AUTOSAR XML (schema 4-2-2)
package /STELLANTIS/EPT/COMSWCs
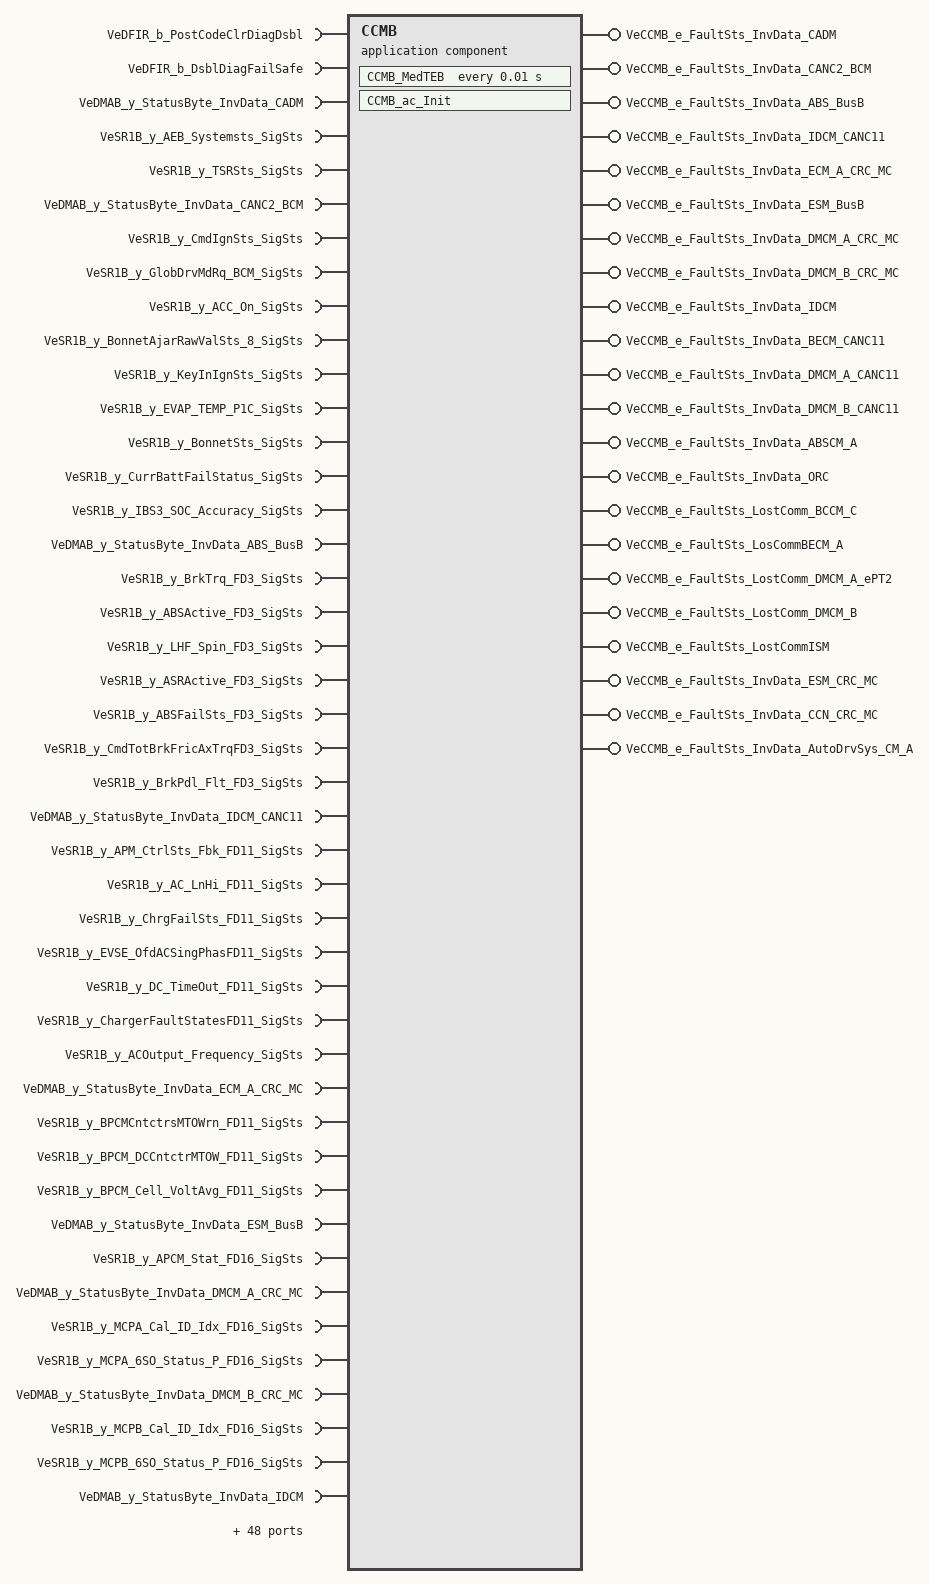
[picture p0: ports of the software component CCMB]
  application sw component type CCMB
    92 x require port, all with nonqueued-receiver-com-spec{data-element=Value, init-value=0}:
      VeDFIR_b_PostCodeClrDiagDsbl: variation-point={short-label=vpVeDFIR_b_PostCodeClrDiagDsbl, sw-syscond=1}, required-interface=VeDFIR_b_PostCodeClrDiagDsbl
      VeDFIR_b_DsblDiagFailSafe: variation-point={short-label=vpVeDFIR_b_DsblDiagFailSafe, sw-syscond=1}, required-interface=VeDFIR_b_DsblDiagFailSafe
      VeDMAB_y_StatusByte_InvData_CADM: variation-point={short-label=vpVeDMAB_y_StatusByte_InvData_CADM, sw-syscond=1}, required-interface=VeDMAB_y_StatusByte_InvData_CADM
      VeSR1B_y_AEB_Systemsts_SigSts: variation-point={short-label=vpVeSR1B_y_AEB_Systemsts_SigSts, sw-syscond=1}, required-interface=VeSR1B_y_AEB_Systemsts_SigSts
      VeSR1B_y_TSRSts_SigSts: variation-point={short-label=vpVeSR1B_y_TSRSts_SigSts, sw-syscond=1}, required-interface=VeSR1B_y_TSRSts_SigSts
      VeDMAB_y_StatusByte_InvData_CANC2_BCM: variation-point={short-label=vpVeDMAB_y_StatusByte_InvData_CANC2_BCM, sw-syscond=1}, required-interface=VeDMAB_y_StatusByte_InvData_CANC2_BCM
      VeSR1B_y_CmdIgnSts_SigSts: variation-point={short-label=vpVeSR1B_y_CmdIgnSts_SigSts, sw-syscond=1}, required-interface=VeSR1B_y_CmdIgnSts_SigSts
      VeSR1B_y_GlobDrvMdRq_BCM_SigSts: variation-point={short-label=vpVeSR1B_y_GlobDrvMdRq_BCM_SigSts, sw-syscond=1}, required-interface=VeSR1B_y_GlobDrvMdRq_BCM_SigSts
      VeSR1B_y_ACC_On_SigSts: variation-point={short-label=vpVeSR1B_y_ACC_On_SigSts, sw-syscond=1}, required-interface=VeSR1B_y_ACC_On_SigSts
      VeSR1B_y_BonnetAjarRawValSts_8_SigSts: variation-point={short-label=vpVeSR1B_y_BonnetAjarRawValSts_8_SigSts, sw-syscond=1}, required-interface=VeSR1B_y_BonnetAjarRawValSts_8_SigSts
      VeSR1B_y_KeyInIgnSts_SigSts: variation-point={short-label=vpVeSR1B_y_KeyInIgnSts_SigSts, sw-syscond=1}, required-interface=VeSR1B_y_KeyInIgnSts_SigSts
      VeSR1B_y_EVAP_TEMP_P1C_SigSts: variation-point={short-label=vpVeSR1B_y_EVAP_TEMP_P1C_SigSts, sw-syscond=1}, required-interface=VeSR1B_y_EVAP_TEMP_P1C_SigSts
      VeSR1B_y_BonnetSts_SigSts: variation-point={short-label=vpVeSR1B_y_BonnetSts_SigSts, sw-syscond=1}, required-interface=VeSR1B_y_BonnetSts_SigSts
      VeSR1B_y_CurrBattFailStatus_SigSts: variation-point={short-label=vpVeSR1B_y_CurrBattFailStatus_SigSts, sw-syscond=1}, required-interface=VeSR1B_y_CurrBattFailStatus_SigSts
      VeSR1B_y_IBS3_SOC_Accuracy_SigSts: variation-point={short-label=vpVeSR1B_y_IBS3_SOC_Accuracy_SigSts, sw-syscond=1}, required-interface=VeSR1B_y_IBS3_SOC_Accuracy_SigSts
      VeDMAB_y_StatusByte_InvData_ABS_BusB: variation-point={short-label=vpVeDMAB_y_StatusByte_InvData_ABS_BusB, sw-syscond=1}, required-interface=VeDMAB_y_StatusByte_InvData_ABS_BusB
      VeSR1B_y_BrkTrq_FD3_SigSts: variation-point={short-label=vpVeSR1B_y_BrkTrq_FD3_SigSts, sw-syscond=1}, required-interface=VeSR1B_y_BrkTrq_FD3_SigSts
      VeSR1B_y_ABSActive_FD3_SigSts: variation-point={short-label=vpVeSR1B_y_ABSActive_FD3_SigSts, sw-syscond=1}, required-interface=VeSR1B_y_ABSActive_FD3_SigSts
      VeSR1B_y_LHF_Spin_FD3_SigSts: variation-point={short-label=vpVeSR1B_y_LHF_Spin_FD3_SigSts, sw-syscond=1}, required-interface=VeSR1B_y_LHF_Spin_FD3_SigSts
      VeSR1B_y_ASRActive_FD3_SigSts: variation-point={short-label=vpVeSR1B_y_ASRActive_FD3_SigSts, sw-syscond=1}, required-interface=VeSR1B_y_ASRActive_FD3_SigSts
      VeSR1B_y_ABSFailSts_FD3_SigSts: variation-point={short-label=vpVeSR1B_y_ABSFailSts_FD3_SigSts, sw-syscond=1}, required-interface=VeSR1B_y_ABSFailSts_FD3_SigSts
      VeSR1B_y_CmdTotBrkFricAxTrqFD3_SigSts: variation-point={short-label=vpVeSR1B_y_CmdTotBrkFricAxTrqFD3_SigSts, sw-syscond=1}, required-interface=VeSR1B_y_CmdTotBrkFricAxTrqFD3_SigSts
      VeSR1B_y_BrkPdl_Flt_FD3_SigSts: variation-point={short-label=vpVeSR1B_y_BrkPdl_Flt_FD3_SigSts, sw-syscond=1}, required-interface=VeSR1B_y_BrkPdl_Flt_FD3_SigSts
      VeDMAB_y_StatusByte_InvData_IDCM_CANC11: variation-point={short-label=vpVeDMAB_y_StatusByte_InvData_IDCM_CANC11, sw-syscond=1}, required-interface=VeDMAB_y_StatusByte_InvData_IDCM_CANC11
      VeSR1B_y_APM_CtrlSts_Fbk_FD11_SigSts: variation-point={short-label=vpVeSR1B_y_APM_CtrlSts_Fbk_FD11_SigSts, sw-syscond=1}, required-interface=VeSR1B_y_APM_CtrlSts_Fbk_FD11_SigSts
      VeSR1B_y_AC_LnHi_FD11_SigSts: variation-point={short-label=vpVeSR1B_y_AC_LnHi_FD11_SigSts, sw-syscond=1}, required-interface=VeSR1B_y_AC_LnHi_FD11_SigSts
      VeSR1B_y_ChrgFailSts_FD11_SigSts: variation-point={short-label=vpVeSR1B_y_ChrgFailSts_FD11_SigSts, sw-syscond=1}, required-interface=VeSR1B_y_ChrgFailSts_FD11_SigSts
      VeSR1B_y_EVSE_OfdACSingPhasFD11_SigSts: variation-point={short-label=vpVeSR1B_y_EVSE_OfdACSingPhasFD11_SigSts, sw-syscond=1}, required-interface=VeSR1B_y_EVSE_OfdACSingPhasFD11_SigSts
      VeSR1B_y_DC_TimeOut_FD11_SigSts: variation-point={short-label=vpVeSR1B_y_DC_TimeOut_FD11_SigSts, sw-syscond=1}, required-interface=VeSR1B_y_DC_TimeOut_FD11_SigSts
      VeSR1B_y_ChargerFaultStatesFD11_SigSts: variation-point={short-label=vpVeSR1B_y_ChargerFaultStatesFD11_SigSts, sw-syscond=1}, required-interface=VeSR1B_y_ChargerFaultStatesFD11_SigSts
      VeSR1B_y_ACOutput_Frequency_SigSts: variation-point={short-label=vpVeSR1B_y_ACOutput_Frequency_SigSts, sw-syscond=1}, required-interface=VeSR1B_y_ACOutput_Frequency_SigSts
      VeDMAB_y_StatusByte_InvData_ECM_A_CRC_MC: variation-point={short-label=vpVeDMAB_y_StatusByte_InvData_ECM_A_CRC_MC, sw-syscond=1}, required-interface=VeDMAB_y_StatusByte_InvData_ECM_A_CRC_MC
      VeSR1B_y_BPCMCntctrsMTOWrn_FD11_SigSts: variation-point={short-label=vpVeSR1B_y_BPCMCntctrsMTOWrn_FD11_SigSts, sw-syscond=1}, required-interface=VeSR1B_y_BPCMCntctrsMTOWrn_FD11_SigSts
      VeSR1B_y_BPCM_DCCntctrMTOW_FD11_SigSts: variation-point={short-label=vpVeSR1B_y_BPCM_DCCntctrMTOW_FD11_SigSts, sw-syscond=1}, required-interface=VeSR1B_y_BPCM_DCCntctrMTOW_FD11_SigSts
      VeSR1B_y_BPCM_Cell_VoltAvg_FD11_SigSts: variation-point={short-label=vpVeSR1B_y_BPCM_Cell_VoltAvg_FD11_SigSts, sw-syscond=1}, required-interface=VeSR1B_y_BPCM_Cell_VoltAvg_FD11_SigSts
      VeDMAB_y_StatusByte_InvData_ESM_BusB: variation-point={short-label=vpVeDMAB_y_StatusByte_InvData_ESM_BusB, sw-syscond=1}, required-interface=VeDMAB_y_StatusByte_InvData_ESM_BusB
      VeSR1B_y_APCM_Stat_FD16_SigSts: variation-point={short-label=vpVeSR1B_y_APCM_Stat_FD16_SigSts, sw-syscond=1}, required-interface=VeSR1B_y_APCM_Stat_FD16_SigSts
      VeDMAB_y_StatusByte_InvData_DMCM_A_CRC_MC: variation-point={short-label=vpVeDMAB_y_StatusByte_InvData_DMCM_A_CRC_MC, sw-syscond=1}, required-interface=VeDMAB_y_StatusByte_InvData_DMCM_A_CRC_MC
      VeSR1B_y_MCPA_Cal_ID_Idx_FD16_SigSts: variation-point={short-label=vpVeSR1B_y_MCPA_Cal_ID_Idx_FD16_SigSts, sw-syscond=1}, required-interface=VeSR1B_y_MCPA_Cal_ID_Idx_FD16_SigSts
      VeSR1B_y_MCPA_6SO_Status_P_FD16_SigSts: variation-point={short-label=vpVeSR1B_y_MCPA_6SO_Status_P_FD16_SigSts, sw-syscond=1}, required-interface=VeSR1B_y_MCPA_6SO_Status_P_FD16_SigSts
      VeDMAB_y_StatusByte_InvData_DMCM_B_CRC_MC: variation-point={short-label=vpVeDMAB_y_StatusByte_InvData_DMCM_B_CRC_MC, sw-syscond=1}, required-interface=VeDMAB_y_StatusByte_InvData_DMCM_B_CRC_MC
      VeSR1B_y_MCPB_Cal_ID_Idx_FD16_SigSts: variation-point={short-label=vpVeSR1B_y_MCPB_Cal_ID_Idx_FD16_SigSts, sw-syscond=1}, required-interface=VeSR1B_y_MCPB_Cal_ID_Idx_FD16_SigSts
      VeSR1B_y_MCPB_6SO_Status_P_FD16_SigSts: variation-point={short-label=vpVeSR1B_y_MCPB_6SO_Status_P_FD16_SigSts, sw-syscond=1}, required-interface=VeSR1B_y_MCPB_6SO_Status_P_FD16_SigSts
      VeDMAB_y_StatusByte_InvData_IDCM: variation-point={short-label=vpVeDMAB_y_StatusByte_InvData_IDCM, sw-syscond=1}, required-interface=VeDMAB_y_StatusByte_InvData_IDCM
      VeSR1B_y_APM_CtrlSts_Fbk_FD5_SigSts: variation-point={short-label=vpVeSR1B_y_APM_CtrlSts_Fbk_FD5_SigSts, sw-syscond=1}, required-interface=VeSR1B_y_APM_CtrlSts_Fbk_FD5_SigSts
      VeSR1B_y_AC_LnHi_FD5_SigSts: variation-point={short-label=vpVeSR1B_y_AC_LnHi_FD5_SigSts, sw-syscond=1}, required-interface=VeSR1B_y_AC_LnHi_FD5_SigSts
      VeSR1B_y_DC_TimeOut_FD5_SigSts: variation-point={short-label=vpVeSR1B_y_DC_TimeOut_FD5_SigSts, sw-syscond=1}, required-interface=VeSR1B_y_DC_TimeOut_FD5_SigSts
      VeSR1B_y_Charger_FaultStatesFD5_SigSts: variation-point={short-label=vpVeSR1B_y_Charger_FaultStatesFD5_SigSts, sw-syscond=1}, required-interface=VeSR1B_y_Charger_FaultStatesFD5_SigSts
      VeDMAB_y_StatusByte_InvData_BECM_CANC11: variation-point={short-label=vpVeDMAB_y_StatusByte_InvData_BECM_CANC11, sw-syscond=1}, required-interface=VeDMAB_y_StatusByte_InvData_BECM_CANC11
      VeSR1B_y_BPCMCntctrsMTOWrn_FD5_SigSts: variation-point={short-label=vpVeSR1B_y_BPCMCntctrsMTOWrn_FD5_SigSts, sw-syscond=1}, required-interface=VeSR1B_y_BPCMCntctrsMTOWrn_FD5_SigSts
      VeSR1B_y_BPCM_DCCntctrMTOW_FD5_SigSts: variation-point={short-label=vpVeSR1B_y_BPCM_DCCntctrMTOW_FD5_SigSts, sw-syscond=1}, required-interface=VeSR1B_y_BPCM_DCCntctrMTOW_FD5_SigSts
      VeSR1B_y_BPCM_Cell_VoltAvg_FD5_SigSts: variation-point={short-label=vpVeSR1B_y_BPCM_Cell_VoltAvg_FD5_SigSts, sw-syscond=1}, required-interface=VeSR1B_y_BPCM_Cell_VoltAvg_FD5_SigSts
      VeDMAB_y_StatusByte_InvData_DMCM_A_CANC11: variation-point={short-label=vpVeDMAB_y_StatusByte_InvData_DMCM_A_CANC11, sw-syscond=1}, required-interface=VeDMAB_y_StatusByte_InvData_DMCM_A_CANC11
      VeSR1B_y_MCPA_Cal_ID_Idx_FD5_SigSts: variation-point={short-label=vpVeSR1B_y_MCPA_Cal_ID_Idx_FD5_SigSts, sw-syscond=1}, required-interface=VeSR1B_y_MCPA_Cal_ID_Idx_FD5_SigSts
      VeSR1B_y_MCPA_6SO_Status_P_FD5_SigSts: variation-point={short-label=vpVeSR1B_y_MCPA_6SO_Status_P_FD5_SigSts, sw-syscond=1}, required-interface=VeSR1B_y_MCPA_6SO_Status_P_FD5_SigSts
      VeDMAB_y_StatusByte_InvData_DMCM_B_CANC11: variation-point={short-label=vpVeDMAB_y_StatusByte_InvData_DMCM_B_CANC11, sw-syscond=1}, required-interface=VeDMAB_y_StatusByte_InvData_DMCM_B_CANC11
      VeSR1B_y_MCPB_Cal_ID_Idx_FD5_SigSts: variation-point={short-label=vpVeSR1B_y_MCPB_Cal_ID_Idx_FD5_SigSts, sw-syscond=1}, required-interface=VeSR1B_y_MCPB_Cal_ID_Idx_FD5_SigSts
      VeSR1B_y_MCPB_6SO_Status_P_FD5_SigSts: variation-point={short-label=vpVeSR1B_y_MCPB_6SO_Status_P_FD5_SigSts, sw-syscond=1}, required-interface=VeSR1B_y_MCPB_6SO_Status_P_FD5_SigSts
      VeDMAB_y_StatusByte_InvData_ABSCM_A: variation-point={short-label=vpVeDMAB_y_StatusByte_InvData_ABSCM_A, sw-syscond=1}, required-interface=VeDMAB_y_StatusByte_InvData_ABSCM_A
      VeSR1B_y_REF_VEH_SPEED_FD14_SigSts: variation-point={short-label=vpVeSR1B_y_REF_VEH_SPEED_FD14_SigSts, sw-syscond=1}, required-interface=VeSR1B_y_REF_VEH_SPEED_FD14_SigSts
      VeSR1B_y_Brk_Stat_FD14_SigSts: variation-point={short-label=vpVeSR1B_y_Brk_Stat_FD14_SigSts, sw-syscond=1}, required-interface=VeSR1B_y_Brk_Stat_FD14_SigSts
      VeSR1B_y_LatAcceltnOffset_BSM_SigSts: variation-point={short-label=vpVeSR1B_y_LatAcceltnOffset_BSM_SigSts, sw-syscond=1}, required-interface=VeSR1B_y_LatAcceltnOffset_BSM_SigSts
      VeSR1B_y_ASRActive_FD14_SigSts: variation-point={short-label=vpVeSR1B_y_ASRActive_FD14_SigSts, sw-syscond=1}, required-interface=VeSR1B_y_ASRActive_FD14_SigSts
      VeSR1B_y_ABSFailSts_FD14_SigSts: variation-point={short-label=vpVeSR1B_y_ABSFailSts_FD14_SigSts, sw-syscond=1}, required-interface=VeSR1B_y_ABSFailSts_FD14_SigSts
      VeSR1B_y_CmdTotBrkFricAxTrqFD14_SigSts: variation-point={short-label=vpVeSR1B_y_CmdTotBrkFricAxTrqFD14_SigSts, sw-syscond=1}, required-interface=VeSR1B_y_CmdTotBrkFricAxTrqFD14_SigSts
      VeSR1B_y_BrakePdlPosn_FD14_SigSts: variation-point={short-label=vpVeSR1B_y_BrakePdlPosn_FD14_SigSts, sw-syscond=1}, required-interface=VeSR1B_y_BrakePdlPosn_FD14_SigSts
      VeDMAB_y_StatusByte_InvData_ORC: variation-point={short-label=vpVeDMAB_y_StatusByte_InvData_ORC, sw-syscond=1}, required-interface=VeDMAB_y_StatusByte_InvData_ORC
      VeSR1B_y_IMPACTCommand_FD14_SigSts: variation-point={short-label=vpVeSR1B_y_IMPACTCommand_FD14_SigSts, sw-syscond=1}, required-interface=VeSR1B_y_IMPACTCommand_FD14_SigSts
      VeSR1B_y_LatAcceleration_FD14_SigSts: variation-point={short-label=vpVeSR1B_y_LatAcceleration_FD14_SigSts, sw-syscond=1}, required-interface=VeSR1B_y_LatAcceleration_FD14_SigSts
      VeDMAB_y_StatusByte_LostComm_BCCM_C: variation-point={short-label=vpVeDMAB_y_StatusByte_LostComm_BCCM_C, sw-syscond=1}, required-interface=VeDMAB_y_StatusByte_LostComm_BCCM_C
      VeCRDB_y_APM_CtrlSts_Fbk_SigSts: variation-point={short-label=vpVeCRDB_y_APM_CtrlSts_Fbk_SigSts, sw-syscond=1}, required-interface=VeCRDB_y_APM_CtrlSts_Fbk_SigSts
      VeCRDB_y_AC_LnHi_SigSts: variation-point={short-label=vpVeCRDB_y_AC_LnHi_SigSts, sw-syscond=1}, required-interface=VeCRDB_y_AC_LnHi_SigSts
      VeCRDB_y_DC_TimeOut_SigSts: variation-point={short-label=vpVeCRDB_y_DC_TimeOut_SigSts, sw-syscond=1}, required-interface=VeCRDB_y_DC_TimeOut_SigSts
      VeCRDB_y_ChargerFaultStates_SigSts: variation-point={short-label=vpVeCRDB_y_ChargerFaultStates_SigSts, sw-syscond=1}, required-interface=VeCRDB_y_ChargerFaultStates_SigSts
      VeDMAB_y_StatusByte_LosCommBECM_A: variation-point={short-label=vpVeDMAB_y_StatusByte_LosCommBECM_A, sw-syscond=1}, required-interface=VeDMAB_y_StatusByte_LosCommBECM_A
      VeCRDB_y_BPCMCntctrsMTOWrn_SigSts: variation-point={short-label=vpVeCRDB_y_BPCMCntctrsMTOWrn_SigSts, sw-syscond=1}, required-interface=VeCRDB_y_BPCMCntctrsMTOWrn_SigSts
      VeCRDB_y_BPCM_DCCntctrMTOW_SigSts: variation-point={short-label=vpVeCRDB_y_BPCM_DCCntctrMTOW_SigSts, sw-syscond=1}, required-interface=VeCRDB_y_BPCM_DCCntctrMTOW_SigSts
      VeCRDB_y_BPCM_Cell_VoltAvg_SigSts: variation-point={short-label=vpVeCRDB_y_BPCM_Cell_VoltAvg_SigSts, sw-syscond=1}, required-interface=VeCRDB_y_BPCM_Cell_VoltAvg_SigSts
      VeDMAB_y_StatusByte_LostComm_DMCM_A_ePT2: variation-point={short-label=vpVeDMAB_y_StatusByte_LostComm_DMCM_A_ePT2, sw-syscond=1}, required-interface=VeDMAB_y_StatusByte_LostComm_DMCM_A_ePT2
      VeCRDB_y_MCPA_Cal_ID_Idx_SigSts: variation-point={short-label=vpVeCRDB_y_MCPA_Cal_ID_Idx_SigSts, sw-syscond=1}, required-interface=VeCRDB_y_MCPA_Cal_ID_Idx_SigSts
      VeCRDB_y_MCPA_6SO_Status_P_SigSts: variation-point={short-label=vpVeCRDB_y_MCPA_6SO_Status_P_SigSts, sw-syscond=1}, required-interface=VeCRDB_y_MCPA_6SO_Status_P_SigSts
      VeDMAB_y_StatusByte_LostComm_DMCM_B: variation-point={short-label=vpVeDMAB_y_StatusByte_LostComm_DMCM_B, sw-syscond=1}, required-interface=VeDMAB_y_StatusByte_LostComm_DMCM_B
      VeCRDB_y_MCPB_Cal_ID_Idx_SigSts: variation-point={short-label=vpVeCRDB_y_MCPB_Cal_ID_Idx_SigSts, sw-syscond=1}, required-interface=VeCRDB_y_MCPB_Cal_ID_Idx_SigSts
      VeCRDB_y_MCPB_6SO_Status_P_SigSts: variation-point={short-label=vpVeCRDB_y_MCPB_6SO_Status_P_SigSts, sw-syscond=1}, required-interface=VeCRDB_y_MCPB_6SO_Status_P_SigSts
      VeDMAB_y_StatusByte_LostCommISM: variation-point={short-label=vpVeDMAB_y_StatusByte_LostCommISM, sw-syscond=1}, required-interface=VeDMAB_y_StatusByte_LostCommISM
      VeDMAB_y_StatusByte_InvData_ESM_CRC_MC: variation-point={short-label=vpVeDMAB_y_StatusByte_InvData_ESM_CRC_MC, sw-syscond=1}, required-interface=VeDMAB_y_StatusByte_InvData_ESM_CRC_MC
      VeSR1B_y_APCM_Stat_FD3_SigSts: variation-point={short-label=vpVeSR1B_y_APCM_Stat_FD3_SigSts, sw-syscond=1}, required-interface=VeSR1B_y_APCM_Stat_FD3_SigSts
      VeDMAB_y_StatusByte_InvData_CCN_CRC_MC: variation-point={short-label=vpVeDMAB_y_StatusByte_InvData_CCN_CRC_MC, sw-syscond=1}, required-interface=VeDMAB_y_StatusByte_InvData_CCN_CRC_MC
      VeSR1B_y_Creep_SigSts: variation-point={short-label=vpVeSR1B_y_Creep_SigSts, sw-syscond=1}, required-interface=VeSR1B_y_Creep_SigSts
      VeDMAB_y_StatusByte_InvData_AutoDrvSys_CM_A: variation-point={short-label=vpVeDMAB_y_StatusByte_InvData_AutoDrvSys_CM_A, sw-syscond=1}, required-interface=VeDMAB_y_StatusByte_InvData_AutoDrvSys_CM_A
      VeSR1B_y_ACC_Systemsts_SigSts: variation-point={short-label=vpVeSR1B_y_ACC_Systemsts_SigSts, sw-syscond=1}, required-interface=VeSR1B_y_ACC_Systemsts_SigSts
      VeSR1B_y_ACC_Blind_SigSts: variation-point={short-label=vpVeSR1B_y_ACC_Blind_SigSts, sw-syscond=1}, required-interface=VeSR1B_y_ACC_Blind_SigSts
    22 x provide port, all with nonqueued-sender-com-spec{data-element=Value, init-value=CeDFIB_e_Init}:
      VeCCMB_e_FaultSts_InvData_CADM: variation-point={short-label=vpVeCCMB_e_FaultSts_InvData_CADM, sw-syscond=1}, provided-interface=VeCCMB_e_FaultSts_InvData_CADM
      VeCCMB_e_FaultSts_InvData_CANC2_BCM: variation-point={short-label=vpVeCCMB_e_FaultSts_InvData_CANC2_BCM, sw-syscond=1}, provided-interface=VeCCMB_e_FaultSts_InvData_CANC2_BCM
      VeCCMB_e_FaultSts_InvData_ABS_BusB: variation-point={short-label=vpVeCCMB_e_FaultSts_InvData_ABS_BusB, sw-syscond=1}, provided-interface=VeCCMB_e_FaultSts_InvData_ABS_BusB
      VeCCMB_e_FaultSts_InvData_IDCM_CANC11: variation-point={short-label=vpVeCCMB_e_FaultSts_InvData_IDCM_CANC11, sw-syscond=1}, provided-interface=VeCCMB_e_FaultSts_InvData_IDCM_CANC11
      VeCCMB_e_FaultSts_InvData_ECM_A_CRC_MC: variation-point={short-label=vpVeCCMB_e_FaultSts_InvData_ECM_A_CRC_MC, sw-syscond=1}, provided-interface=VeCCMB_e_FaultSts_InvData_ECM_A_CRC_MC
      VeCCMB_e_FaultSts_InvData_ESM_BusB: variation-point={short-label=vpVeCCMB_e_FaultSts_InvData_ESM_BusB, sw-syscond=1}, provided-interface=VeCCMB_e_FaultSts_InvData_ESM_BusB
      VeCCMB_e_FaultSts_InvData_DMCM_A_CRC_MC: variation-point={short-label=vpVeCCMB_e_FaultSts_InvData_DMCM_A_CRC_MC, sw-syscond=1}, provided-interface=VeCCMB_e_FaultSts_InvData_DMCM_A_CRC_MC
      VeCCMB_e_FaultSts_InvData_DMCM_B_CRC_MC: variation-point={short-label=vpVeCCMB_e_FaultSts_InvData_DMCM_B_CRC_MC, sw-syscond=1}, provided-interface=VeCCMB_e_FaultSts_InvData_DMCM_B_CRC_MC
      VeCCMB_e_FaultSts_InvData_IDCM: variation-point={short-label=vpVeCCMB_e_FaultSts_InvData_IDCM, sw-syscond=1}, provided-interface=VeCCMB_e_FaultSts_InvData_IDCM
      VeCCMB_e_FaultSts_InvData_BECM_CANC11: variation-point={short-label=vpVeCCMB_e_FaultSts_InvData_BECM_CANC11, sw-syscond=1}, provided-interface=VeCCMB_e_FaultSts_InvData_BECM_CANC11
      VeCCMB_e_FaultSts_InvData_DMCM_A_CANC11: variation-point={short-label=vpVeCCMB_e_FaultSts_InvData_DMCM_A_CANC11, sw-syscond=1}, provided-interface=VeCCMB_e_FaultSts_InvData_DMCM_A_CANC11
      VeCCMB_e_FaultSts_InvData_DMCM_B_CANC11: variation-point={short-label=vpVeCCMB_e_FaultSts_InvData_DMCM_B_CANC11, sw-syscond=1}, provided-interface=VeCCMB_e_FaultSts_InvData_DMCM_B_CANC11
      VeCCMB_e_FaultSts_InvData_ABSCM_A: variation-point={short-label=vpVeCCMB_e_FaultSts_InvData_ABSCM_A, sw-syscond=1}, provided-interface=VeCCMB_e_FaultSts_InvData_ABSCM_A
      VeCCMB_e_FaultSts_InvData_ORC: variation-point={short-label=vpVeCCMB_e_FaultSts_InvData_ORC, sw-syscond=1}, provided-interface=VeCCMB_e_FaultSts_InvData_ORC
      VeCCMB_e_FaultSts_LostComm_BCCM_C: variation-point={short-label=vpVeCCMB_e_FaultSts_LostComm_BCCM_C, sw-syscond=1}, provided-interface=VeCCMB_e_FaultSts_LostComm_BCCM_C
      VeCCMB_e_FaultSts_LosCommBECM_A: variation-point={short-label=vpVeCCMB_e_FaultSts_LosCommBECM_A, sw-syscond=1}, provided-interface=VeCCMB_e_FaultSts_LosCommBECM_A
      VeCCMB_e_FaultSts_LostComm_DMCM_A_ePT2: variation-point={short-label=vpVeCCMB_e_FaultSts_LostComm_DMCM_A_ePT2, sw-syscond=1}, provided-interface=VeCCMB_e_FaultSts_LostComm_DMCM_A_ePT2
      VeCCMB_e_FaultSts_LostComm_DMCM_B: variation-point={short-label=vpVeCCMB_e_FaultSts_LostComm_DMCM_B, sw-syscond=1}, provided-interface=VeCCMB_e_FaultSts_LostComm_DMCM_B
      VeCCMB_e_FaultSts_LostCommISM: variation-point={short-label=vpVeCCMB_e_FaultSts_LostCommISM, sw-syscond=1}, provided-interface=VeCCMB_e_FaultSts_LostCommISM
      VeCCMB_e_FaultSts_InvData_ESM_CRC_MC: variation-point={short-label=vpVeCCMB_e_FaultSts_InvData_ESM_CRC_MC, sw-syscond=1}, provided-interface=VeCCMB_e_FaultSts_InvData_ESM_CRC_MC
      VeCCMB_e_FaultSts_InvData_CCN_CRC_MC: variation-point={short-label=vpVeCCMB_e_FaultSts_InvData_CCN_CRC_MC, sw-syscond=1}, provided-interface=VeCCMB_e_FaultSts_InvData_CCN_CRC_MC
      VeCCMB_e_FaultSts_InvData_AutoDrvSys_CM_A: variation-point={short-label=vpVeCCMB_e_FaultSts_InvData_AutoDrvSys_CM_A, sw-syscond=1}, provided-interface=VeCCMB_e_FaultSts_InvData_AutoDrvSys_CM_A
    behavior IB_CCMB: data-type-mapping=msADTtoIDTMapping, handle-termination-and-restart=NO-SUPPORT
      timing event Event_MedTEB: start-on-event=CCMB_MedTEB, period=0.01
      init event Event_CCMB_ac_Init: start-on-event=CCMB_ac_Init
      runnable CCMB_ac_Init
        data-send-points:
          22 x access:
            OUT_VeCCMB_e_FaultSts_InvData_CADM_Value: accessed-variable=VeCCMB_e_FaultSts_InvData_CADM.Value, variation-point={short-label=vpOUT_VeCCMB_e_FaultSts_InvData_CADM_Value, sw-syscond=1}
            OUT_VeCCMB_e_FaultSts_InvData_CANC2_BCM_Value: accessed-variable=VeCCMB_e_FaultSts_InvData_CANC2_BCM.Value, variation-point={short-label=vpOUT_VeCCMB_e_FaultSts_InvData_CANC2_BCM_Value, sw-syscond=1}
            OUT_VeCCMB_e_FaultSts_InvData_ABS_BusB_Value: accessed-variable=VeCCMB_e_FaultSts_InvData_ABS_BusB.Value, variation-point={short-label=vpOUT_VeCCMB_e_FaultSts_InvData_ABS_BusB_Value, sw-syscond=1}
            OUT_VeCCMB_e_FaultSts_InvData_IDCM_CANC11_Value: accessed-variable=VeCCMB_e_FaultSts_InvData_IDCM_CANC11.Value, variation-point={short-label=vpOUT_VeCCMB_e_FaultSts_InvData_IDCM_CANC11_Value, sw-syscond=1}
            OUT_VeCCMB_e_FaultSts_InvData_ECM_A_CRC_MC_Value: accessed-variable=VeCCMB_e_FaultSts_InvData_ECM_A_CRC_MC.Value, variation-point={short-label=vpOUT_VeCCMB_e_FaultSts_InvData_ECM_A_CRC_MC_Value, sw-syscond=1}
            OUT_VeCCMB_e_FaultSts_InvData_ESM_BusB_Value: accessed-variable=VeCCMB_e_FaultSts_InvData_ESM_BusB.Value, variation-point={short-label=vpOUT_VeCCMB_e_FaultSts_InvData_ESM_BusB_Value, sw-syscond=1}
            OUT_VeCCMB_e_FaultSts_InvData_DMCM_A_CRC_MC_Value: accessed-variable=VeCCMB_e_FaultSts_InvData_DMCM_A_CRC_MC.Value, variation-point={short-label=vpOUT_VeCCMB_e_FaultSts_InvData_DMCM_A_CRC_MC_Value, sw-syscond=1}
            OUT_VeCCMB_e_FaultSts_InvData_DMCM_B_CRC_MC_Value: accessed-variable=VeCCMB_e_FaultSts_InvData_DMCM_B_CRC_MC.Value, variation-point={short-label=vpOUT_VeCCMB_e_FaultSts_InvData_DMCM_B_CRC_MC_Value, sw-syscond=1}
            OUT_VeCCMB_e_FaultSts_InvData_IDCM_Value: accessed-variable=VeCCMB_e_FaultSts_InvData_IDCM.Value, variation-point={short-label=vpOUT_VeCCMB_e_FaultSts_InvData_IDCM_Value, sw-syscond=1}
            OUT_VeCCMB_e_FaultSts_InvData_BECM_CANC11_Value: accessed-variable=VeCCMB_e_FaultSts_InvData_BECM_CANC11.Value, variation-point={short-label=vpOUT_VeCCMB_e_FaultSts_InvData_BECM_CANC11_Value, sw-syscond=1}
            OUT_VeCCMB_e_FaultSts_InvData_DMCM_A_CANC11_Value: accessed-variable=VeCCMB_e_FaultSts_InvData_DMCM_A_CANC11.Value, variation-point={short-label=vpOUT_VeCCMB_e_FaultSts_InvData_DMCM_A_CANC11_Value, sw-syscond=1}
            OUT_VeCCMB_e_FaultSts_InvData_DMCM_B_CANC11_Value: accessed-variable=VeCCMB_e_FaultSts_InvData_DMCM_B_CANC11.Value, variation-point={short-label=vpOUT_VeCCMB_e_FaultSts_InvData_DMCM_B_CANC11_Value, sw-syscond=1}
            OUT_VeCCMB_e_FaultSts_InvData_ABSCM_A_Value: accessed-variable=VeCCMB_e_FaultSts_InvData_ABSCM_A.Value, variation-point={short-label=vpOUT_VeCCMB_e_FaultSts_InvData_ABSCM_A_Value, sw-syscond=1}
            OUT_VeCCMB_e_FaultSts_InvData_ORC_Value: accessed-variable=VeCCMB_e_FaultSts_InvData_ORC.Value, variation-point={short-label=vpOUT_VeCCMB_e_FaultSts_InvData_ORC_Value, sw-syscond=1}
            OUT_VeCCMB_e_FaultSts_LostComm_BCCM_C_Value: accessed-variable=VeCCMB_e_FaultSts_LostComm_BCCM_C.Value, variation-point={short-label=vpOUT_VeCCMB_e_FaultSts_LostComm_BCCM_C_Value, sw-syscond=1}
            OUT_VeCCMB_e_FaultSts_LosCommBECM_A_Value: accessed-variable=VeCCMB_e_FaultSts_LosCommBECM_A.Value, variation-point={short-label=vpOUT_VeCCMB_e_FaultSts_LosCommBECM_A_Value, sw-syscond=1}
            OUT_VeCCMB_e_FaultSts_LostComm_DMCM_A_ePT2_Value: accessed-variable=VeCCMB_e_FaultSts_LostComm_DMCM_A_ePT2.Value, variation-point={short-label=vpOUT_VeCCMB_e_FaultSts_LostComm_DMCM_A_ePT2_Value, sw-syscond=1}
            OUT_VeCCMB_e_FaultSts_LostComm_DMCM_B_Value: accessed-variable=VeCCMB_e_FaultSts_LostComm_DMCM_B.Value, variation-point={short-label=vpOUT_VeCCMB_e_FaultSts_LostComm_DMCM_B_Value, sw-syscond=1}
            OUT_VeCCMB_e_FaultSts_LostCommISM_Value: accessed-variable=VeCCMB_e_FaultSts_LostCommISM.Value, variation-point={short-label=vpOUT_VeCCMB_e_FaultSts_LostCommISM_Value, sw-syscond=1}
            OUT_VeCCMB_e_FaultSts_InvData_ESM_CRC_MC_Value: accessed-variable=VeCCMB_e_FaultSts_InvData_ESM_CRC_MC.Value, variation-point={short-label=vpOUT_VeCCMB_e_FaultSts_InvData_ESM_CRC_MC_Value, sw-syscond=1}
            OUT_VeCCMB_e_FaultSts_InvData_CCN_CRC_MC_Value: accessed-variable=VeCCMB_e_FaultSts_InvData_CCN_CRC_MC.Value, variation-point={short-label=vpOUT_VeCCMB_e_FaultSts_InvData_CCN_CRC_MC_Value, sw-syscond=1}
            OUT_VeCCMB_e_FaultSts_InvData_AutoDrvSys_CM_A_Value: accessed-variable=VeCCMB_e_FaultSts_InvData_AutoDrvSys_CM_A.Value, variation-point={short-label=vpOUT_VeCCMB_e_FaultSts_InvData_AutoDrvSys_CM_A_Value, sw-syscond=1}
      runnable CCMB_MedTEB
        data-receive-point-by-arguments:
          92 x access:
            IN_VeCRDB_y_AC_LnHi_SigSts_Value: accessed-variable=VeCRDB_y_AC_LnHi_SigSts.Value, variation-point={short-label=vpIN_VeCRDB_y_AC_LnHi_SigSts_Value, sw-syscond=1}
            IN_VeCRDB_y_APM_CtrlSts_Fbk_SigSts_Value: accessed-variable=VeCRDB_y_APM_CtrlSts_Fbk_SigSts.Value, variation-point={short-label=vpIN_VeCRDB_y_APM_CtrlSts_Fbk_SigSts_Value, sw-syscond=1}
            IN_VeCRDB_y_BPCMCntctrsMTOWrn_SigSts_Value: accessed-variable=VeCRDB_y_BPCMCntctrsMTOWrn_SigSts.Value, variation-point={short-label=vpIN_VeCRDB_y_BPCMCntctrsMTOWrn_SigSts_Value, sw-syscond=1}
            IN_VeCRDB_y_BPCM_Cell_VoltAvg_SigSts_Value: accessed-variable=VeCRDB_y_BPCM_Cell_VoltAvg_SigSts.Value, variation-point={short-label=vpIN_VeCRDB_y_BPCM_Cell_VoltAvg_SigSts_Value, sw-syscond=1}
            IN_VeCRDB_y_BPCM_DCCntctrMTOW_SigSts_Value: accessed-variable=VeCRDB_y_BPCM_DCCntctrMTOW_SigSts.Value, variation-point={short-label=vpIN_VeCRDB_y_BPCM_DCCntctrMTOW_SigSts_Value, sw-syscond=1}
            IN_VeCRDB_y_ChargerFaultStates_SigSts_Value: accessed-variable=VeCRDB_y_ChargerFaultStates_SigSts.Value, variation-point={short-label=vpIN_VeCRDB_y_ChargerFaultStates_SigSts_Value, sw-syscond=1}
            IN_VeCRDB_y_DC_TimeOut_SigSts_Value: accessed-variable=VeCRDB_y_DC_TimeOut_SigSts.Value, variation-point={short-label=vpIN_VeCRDB_y_DC_TimeOut_SigSts_Value, sw-syscond=1}
            IN_VeCRDB_y_MCPA_6SO_Status_P_SigSts_Value: accessed-variable=VeCRDB_y_MCPA_6SO_Status_P_SigSts.Value, variation-point={short-label=vpIN_VeCRDB_y_MCPA_6SO_Status_P_SigSts_Value, sw-syscond=1}
            IN_VeCRDB_y_MCPA_Cal_ID_Idx_SigSts_Value: accessed-variable=VeCRDB_y_MCPA_Cal_ID_Idx_SigSts.Value, variation-point={short-label=vpIN_VeCRDB_y_MCPA_Cal_ID_Idx_SigSts_Value, sw-syscond=1}
            IN_VeCRDB_y_MCPB_6SO_Status_P_SigSts_Value: accessed-variable=VeCRDB_y_MCPB_6SO_Status_P_SigSts.Value, variation-point={short-label=vpIN_VeCRDB_y_MCPB_6SO_Status_P_SigSts_Value, sw-syscond=1}
            IN_VeCRDB_y_MCPB_Cal_ID_Idx_SigSts_Value: accessed-variable=VeCRDB_y_MCPB_Cal_ID_Idx_SigSts.Value, variation-point={short-label=vpIN_VeCRDB_y_MCPB_Cal_ID_Idx_SigSts_Value, sw-syscond=1}
            IN_VeDFIR_b_DsblDiagFailSafe_Value: accessed-variable=VeDFIR_b_DsblDiagFailSafe.Value, variation-point={short-label=vpIN_VeDFIR_b_DsblDiagFailSafe_Value, sw-syscond=1}
            IN_VeDFIR_b_PostCodeClrDiagDsbl_Value: accessed-variable=VeDFIR_b_PostCodeClrDiagDsbl.Value, variation-point={short-label=vpIN_VeDFIR_b_PostCodeClrDiagDsbl_Value, sw-syscond=1}
            IN_VeDMAB_y_StatusByte_InvData_ABSCM_A_Value: accessed-variable=VeDMAB_y_StatusByte_InvData_ABSCM_A.Value, variation-point={short-label=vpIN_VeDMAB_y_StatusByte_InvData_ABSCM_A_Value, sw-syscond=1}
            IN_VeDMAB_y_StatusByte_InvData_ABS_BusB_Value: accessed-variable=VeDMAB_y_StatusByte_InvData_ABS_BusB.Value, variation-point={short-label=vpIN_VeDMAB_y_StatusByte_InvData_ABS_BusB_Value, sw-syscond=1}
            IN_VeDMAB_y_StatusByte_InvData_AutoDrvSys_CM_A_Value: accessed-variable=VeDMAB_y_StatusByte_InvData_AutoDrvSys_CM_A.Value, variation-point={short-label=vpIN_VeDMAB_y_StatusByte_InvData_AutoDrvSys_CM_A_Value, sw-syscond=1}
            IN_VeDMAB_y_StatusByte_InvData_BECM_CANC11_Value: accessed-variable=VeDMAB_y_StatusByte_InvData_BECM_CANC11.Value, variation-point={short-label=vpIN_VeDMAB_y_StatusByte_InvData_BECM_CANC11_Value, sw-syscond=1}
            IN_VeDMAB_y_StatusByte_InvData_CADM_Value: accessed-variable=VeDMAB_y_StatusByte_InvData_CADM.Value, variation-point={short-label=vpIN_VeDMAB_y_StatusByte_InvData_CADM_Value, sw-syscond=1}
            IN_VeDMAB_y_StatusByte_InvData_CANC2_BCM_Value: accessed-variable=VeDMAB_y_StatusByte_InvData_CANC2_BCM.Value, variation-point={short-label=vpIN_VeDMAB_y_StatusByte_InvData_CANC2_BCM_Value, sw-syscond=1}
            IN_VeDMAB_y_StatusByte_InvData_CCN_CRC_MC_Value: accessed-variable=VeDMAB_y_StatusByte_InvData_CCN_CRC_MC.Value, variation-point={short-label=vpIN_VeDMAB_y_StatusByte_InvData_CCN_CRC_MC_Value, sw-syscond=1}
            IN_VeDMAB_y_StatusByte_InvData_DMCM_A_CANC11_Value: accessed-variable=VeDMAB_y_StatusByte_InvData_DMCM_A_CANC11.Value, variation-point={short-label=vpIN_VeDMAB_y_StatusByte_InvData_DMCM_A_CANC11_Value, sw-syscond=1}
            IN_VeDMAB_y_StatusByte_InvData_DMCM_A_CRC_MC_Value: accessed-variable=VeDMAB_y_StatusByte_InvData_DMCM_A_CRC_MC.Value, variation-point={short-label=vpIN_VeDMAB_y_StatusByte_InvData_DMCM_A_CRC_MC_Value, sw-syscond=1}
            IN_VeDMAB_y_StatusByte_InvData_DMCM_B_CANC11_Value: accessed-variable=VeDMAB_y_StatusByte_InvData_DMCM_B_CANC11.Value, variation-point={short-label=vpIN_VeDMAB_y_StatusByte_InvData_DMCM_B_CANC11_Value, sw-syscond=1}
            IN_VeDMAB_y_StatusByte_InvData_DMCM_B_CRC_MC_Value: accessed-variable=VeDMAB_y_StatusByte_InvData_DMCM_B_CRC_MC.Value, variation-point={short-label=vpIN_VeDMAB_y_StatusByte_InvData_DMCM_B_CRC_MC_Value, sw-syscond=1}
            IN_VeDMAB_y_StatusByte_InvData_ECM_A_CRC_MC_Value: accessed-variable=VeDMAB_y_StatusByte_InvData_ECM_A_CRC_MC.Value, variation-point={short-label=vpIN_VeDMAB_y_StatusByte_InvData_ECM_A_CRC_MC_Value, sw-syscond=1}
            IN_VeDMAB_y_StatusByte_InvData_ESM_BusB_Value: accessed-variable=VeDMAB_y_StatusByte_InvData_ESM_BusB.Value, variation-point={short-label=vpIN_VeDMAB_y_StatusByte_InvData_ESM_BusB_Value, sw-syscond=1}
            IN_VeDMAB_y_StatusByte_InvData_ESM_CRC_MC_Value: accessed-variable=VeDMAB_y_StatusByte_InvData_ESM_CRC_MC.Value, variation-point={short-label=vpIN_VeDMAB_y_StatusByte_InvData_ESM_CRC_MC_Value, sw-syscond=1}
            IN_VeDMAB_y_StatusByte_InvData_IDCM_Value: accessed-variable=VeDMAB_y_StatusByte_InvData_IDCM.Value, variation-point={short-label=vpIN_VeDMAB_y_StatusByte_InvData_IDCM_Value, sw-syscond=1}
            IN_VeDMAB_y_StatusByte_InvData_IDCM_CANC11_Value: accessed-variable=VeDMAB_y_StatusByte_InvData_IDCM_CANC11.Value, variation-point={short-label=vpIN_VeDMAB_y_StatusByte_InvData_IDCM_CANC11_Value, sw-syscond=1}
            IN_VeDMAB_y_StatusByte_InvData_ORC_Value: accessed-variable=VeDMAB_y_StatusByte_InvData_ORC.Value, variation-point={short-label=vpIN_VeDMAB_y_StatusByte_InvData_ORC_Value, sw-syscond=1}
            IN_VeDMAB_y_StatusByte_LosCommBECM_A_Value: accessed-variable=VeDMAB_y_StatusByte_LosCommBECM_A.Value, variation-point={short-label=vpIN_VeDMAB_y_StatusByte_LosCommBECM_A_Value, sw-syscond=1}
            IN_VeDMAB_y_StatusByte_LostCommISM_Value: accessed-variable=VeDMAB_y_StatusByte_LostCommISM.Value, variation-point={short-label=vpIN_VeDMAB_y_StatusByte_LostCommISM_Value, sw-syscond=1}
            IN_VeDMAB_y_StatusByte_LostComm_BCCM_C_Value: accessed-variable=VeDMAB_y_StatusByte_LostComm_BCCM_C.Value, variation-point={short-label=vpIN_VeDMAB_y_StatusByte_LostComm_BCCM_C_Value, sw-syscond=1}
            IN_VeDMAB_y_StatusByte_LostComm_DMCM_A_ePT2_Value: accessed-variable=VeDMAB_y_StatusByte_LostComm_DMCM_A_ePT2.Value, variation-point={short-label=vpIN_VeDMAB_y_StatusByte_LostComm_DMCM_A_ePT2_Value, sw-syscond=1}
            IN_VeDMAB_y_StatusByte_LostComm_DMCM_B_Value: accessed-variable=VeDMAB_y_StatusByte_LostComm_DMCM_B.Value, variation-point={short-label=vpIN_VeDMAB_y_StatusByte_LostComm_DMCM_B_Value, sw-syscond=1}
            IN_VeSR1B_y_ABSActive_FD3_SigSts_Value: accessed-variable=VeSR1B_y_ABSActive_FD3_SigSts.Value, variation-point={short-label=vpIN_VeSR1B_y_ABSActive_FD3_SigSts_Value, sw-syscond=1}
            IN_VeSR1B_y_ABSFailSts_FD14_SigSts_Value: accessed-variable=VeSR1B_y_ABSFailSts_FD14_SigSts.Value, variation-point={short-label=vpIN_VeSR1B_y_ABSFailSts_FD14_SigSts_Value, sw-syscond=1}
            IN_VeSR1B_y_ABSFailSts_FD3_SigSts_Value: accessed-variable=VeSR1B_y_ABSFailSts_FD3_SigSts.Value, variation-point={short-label=vpIN_VeSR1B_y_ABSFailSts_FD3_SigSts_Value, sw-syscond=1}
            IN_VeSR1B_y_ACC_Blind_SigSts_Value: accessed-variable=VeSR1B_y_ACC_Blind_SigSts.Value, variation-point={short-label=vpIN_VeSR1B_y_ACC_Blind_SigSts_Value, sw-syscond=1}
            IN_VeSR1B_y_ACC_On_SigSts_Value: accessed-variable=VeSR1B_y_ACC_On_SigSts.Value, variation-point={short-label=vpIN_VeSR1B_y_ACC_On_SigSts_Value, sw-syscond=1}
            IN_VeSR1B_y_ACC_Systemsts_SigSts_Value: accessed-variable=VeSR1B_y_ACC_Systemsts_SigSts.Value, variation-point={short-label=vpIN_VeSR1B_y_ACC_Systemsts_SigSts_Value, sw-syscond=1}
            IN_VeSR1B_y_ACOutput_Frequency_SigSts_Value: accessed-variable=VeSR1B_y_ACOutput_Frequency_SigSts.Value, variation-point={short-label=vpIN_VeSR1B_y_ACOutput_Frequency_SigSts_Value, sw-syscond=1}
            IN_VeSR1B_y_AC_LnHi_FD11_SigSts_Value: accessed-variable=VeSR1B_y_AC_LnHi_FD11_SigSts.Value, variation-point={short-label=vpIN_VeSR1B_y_AC_LnHi_FD11_SigSts_Value, sw-syscond=1}
            IN_VeSR1B_y_AC_LnHi_FD5_SigSts_Value: accessed-variable=VeSR1B_y_AC_LnHi_FD5_SigSts.Value, variation-point={short-label=vpIN_VeSR1B_y_AC_LnHi_FD5_SigSts_Value, sw-syscond=1}
            IN_VeSR1B_y_AEB_Systemsts_SigSts_Value: accessed-variable=VeSR1B_y_AEB_Systemsts_SigSts.Value, variation-point={short-label=vpIN_VeSR1B_y_AEB_Systemsts_SigSts_Value, sw-syscond=1}
            IN_VeSR1B_y_APCM_Stat_FD16_SigSts_Value: accessed-variable=VeSR1B_y_APCM_Stat_FD16_SigSts.Value, variation-point={short-label=vpIN_VeSR1B_y_APCM_Stat_FD16_SigSts_Value, sw-syscond=1}
            IN_VeSR1B_y_APCM_Stat_FD3_SigSts_Value: accessed-variable=VeSR1B_y_APCM_Stat_FD3_SigSts.Value, variation-point={short-label=vpIN_VeSR1B_y_APCM_Stat_FD3_SigSts_Value, sw-syscond=1}
            IN_VeSR1B_y_APM_CtrlSts_Fbk_FD11_SigSts_Value: accessed-variable=VeSR1B_y_APM_CtrlSts_Fbk_FD11_SigSts.Value, variation-point={short-label=vpIN_VeSR1B_y_APM_CtrlSts_Fbk_FD11_SigSts_Value, sw-syscond=1}
            IN_VeSR1B_y_APM_CtrlSts_Fbk_FD5_SigSts_Value: accessed-variable=VeSR1B_y_APM_CtrlSts_Fbk_FD5_SigSts.Value, variation-point={short-label=vpIN_VeSR1B_y_APM_CtrlSts_Fbk_FD5_SigSts_Value, sw-syscond=1}
            IN_VeSR1B_y_ASRActive_FD14_SigSts_Value: accessed-variable=VeSR1B_y_ASRActive_FD14_SigSts.Value, variation-point={short-label=vpIN_VeSR1B_y_ASRActive_FD14_SigSts_Value, sw-syscond=1}
            IN_VeSR1B_y_ASRActive_FD3_SigSts_Value: accessed-variable=VeSR1B_y_ASRActive_FD3_SigSts.Value, variation-point={short-label=vpIN_VeSR1B_y_ASRActive_FD3_SigSts_Value, sw-syscond=1}
            IN_VeSR1B_y_BPCMCntctrsMTOWrn_FD11_SigSts_Value: accessed-variable=VeSR1B_y_BPCMCntctrsMTOWrn_FD11_SigSts.Value, variation-point={short-label=vpIN_VeSR1B_y_BPCMCntctrsMTOWrn_FD11_SigSts_Value, sw-syscond=1}
            IN_VeSR1B_y_BPCMCntctrsMTOWrn_FD5_SigSts_Value: accessed-variable=VeSR1B_y_BPCMCntctrsMTOWrn_FD5_SigSts.Value, variation-point={short-label=vpIN_VeSR1B_y_BPCMCntctrsMTOWrn_FD5_SigSts_Value, sw-syscond=1}
            IN_VeSR1B_y_BPCM_Cell_VoltAvg_FD11_SigSts_Value: accessed-variable=VeSR1B_y_BPCM_Cell_VoltAvg_FD11_SigSts.Value, variation-point={short-label=vpIN_VeSR1B_y_BPCM_Cell_VoltAvg_FD11_SigSts_Value, sw-syscond=1}
            IN_VeSR1B_y_BPCM_Cell_VoltAvg_FD5_SigSts_Value: accessed-variable=VeSR1B_y_BPCM_Cell_VoltAvg_FD5_SigSts.Value, variation-point={short-label=vpIN_VeSR1B_y_BPCM_Cell_VoltAvg_FD5_SigSts_Value, sw-syscond=1}
            IN_VeSR1B_y_BPCM_DCCntctrMTOW_FD11_SigSts_Value: accessed-variable=VeSR1B_y_BPCM_DCCntctrMTOW_FD11_SigSts.Value, variation-point={short-label=vpIN_VeSR1B_y_BPCM_DCCntctrMTOW_FD11_SigSts_Value, sw-syscond=1}
            IN_VeSR1B_y_BPCM_DCCntctrMTOW_FD5_SigSts_Value: accessed-variable=VeSR1B_y_BPCM_DCCntctrMTOW_FD5_SigSts.Value, variation-point={short-label=vpIN_VeSR1B_y_BPCM_DCCntctrMTOW_FD5_SigSts_Value, sw-syscond=1}
            IN_VeSR1B_y_BonnetAjarRawValSts_8_SigSts_Value: accessed-variable=VeSR1B_y_BonnetAjarRawValSts_8_SigSts.Value, variation-point={short-label=vpIN_VeSR1B_y_BonnetAjarRawValSts_8_SigSts_Value, sw-syscond=1}
            IN_VeSR1B_y_BonnetSts_SigSts_Value: accessed-variable=VeSR1B_y_BonnetSts_SigSts.Value, variation-point={short-label=vpIN_VeSR1B_y_BonnetSts_SigSts_Value, sw-syscond=1}
            IN_VeSR1B_y_BrakePdlPosn_FD14_SigSts_Value: accessed-variable=VeSR1B_y_BrakePdlPosn_FD14_SigSts.Value, variation-point={short-label=vpIN_VeSR1B_y_BrakePdlPosn_FD14_SigSts_Value, sw-syscond=1}
            IN_VeSR1B_y_BrkPdl_Flt_FD3_SigSts_Value: accessed-variable=VeSR1B_y_BrkPdl_Flt_FD3_SigSts.Value, variation-point={short-label=vpIN_VeSR1B_y_BrkPdl_Flt_FD3_SigSts_Value, sw-syscond=1}
            IN_VeSR1B_y_BrkTrq_FD3_SigSts_Value: accessed-variable=VeSR1B_y_BrkTrq_FD3_SigSts.Value, variation-point={short-label=vpIN_VeSR1B_y_BrkTrq_FD3_SigSts_Value, sw-syscond=1}
            IN_VeSR1B_y_Brk_Stat_FD14_SigSts_Value: accessed-variable=VeSR1B_y_Brk_Stat_FD14_SigSts.Value, variation-point={short-label=vpIN_VeSR1B_y_Brk_Stat_FD14_SigSts_Value, sw-syscond=1}
            IN_VeSR1B_y_ChargerFaultStatesFD11_SigSts_Value: accessed-variable=VeSR1B_y_ChargerFaultStatesFD11_SigSts.Value, variation-point={short-label=vpIN_VeSR1B_y_ChargerFaultStatesFD11_SigSts_Value, sw-syscond=1}
            IN_VeSR1B_y_Charger_FaultStatesFD5_SigSts_Value: accessed-variable=VeSR1B_y_Charger_FaultStatesFD5_SigSts.Value, variation-point={short-label=vpIN_VeSR1B_y_Charger_FaultStatesFD5_SigSts_Value, sw-syscond=1}
            IN_VeSR1B_y_ChrgFailSts_FD11_SigSts_Value: accessed-variable=VeSR1B_y_ChrgFailSts_FD11_SigSts.Value, variation-point={short-label=vpIN_VeSR1B_y_ChrgFailSts_FD11_SigSts_Value, sw-syscond=1}
            IN_VeSR1B_y_CmdIgnSts_SigSts_Value: accessed-variable=VeSR1B_y_CmdIgnSts_SigSts.Value, variation-point={short-label=vpIN_VeSR1B_y_CmdIgnSts_SigSts_Value, sw-syscond=1}
            IN_VeSR1B_y_CmdTotBrkFricAxTrqFD14_SigSts_Value: accessed-variable=VeSR1B_y_CmdTotBrkFricAxTrqFD14_SigSts.Value, variation-point={short-label=vpIN_VeSR1B_y_CmdTotBrkFricAxTrqFD14_SigSts_Value, sw-syscond=1}
            IN_VeSR1B_y_CmdTotBrkFricAxTrqFD3_SigSts_Value: accessed-variable=VeSR1B_y_CmdTotBrkFricAxTrqFD3_SigSts.Value, variation-point={short-label=vpIN_VeSR1B_y_CmdTotBrkFricAxTrqFD3_SigSts_Value, sw-syscond=1}
            IN_VeSR1B_y_Creep_SigSts_Value: accessed-variable=VeSR1B_y_Creep_SigSts.Value, variation-point={short-label=vpIN_VeSR1B_y_Creep_SigSts_Value, sw-syscond=1}
            IN_VeSR1B_y_CurrBattFailStatus_SigSts_Value: accessed-variable=VeSR1B_y_CurrBattFailStatus_SigSts.Value, variation-point={short-label=vpIN_VeSR1B_y_CurrBattFailStatus_SigSts_Value, sw-syscond=1}
            IN_VeSR1B_y_DC_TimeOut_FD11_SigSts_Value: accessed-variable=VeSR1B_y_DC_TimeOut_FD11_SigSts.Value, variation-point={short-label=vpIN_VeSR1B_y_DC_TimeOut_FD11_SigSts_Value, sw-syscond=1}
            IN_VeSR1B_y_DC_TimeOut_FD5_SigSts_Value: accessed-variable=VeSR1B_y_DC_TimeOut_FD5_SigSts.Value, variation-point={short-label=vpIN_VeSR1B_y_DC_TimeOut_FD5_SigSts_Value, sw-syscond=1}
            IN_VeSR1B_y_EVAP_TEMP_P1C_SigSts_Value: accessed-variable=VeSR1B_y_EVAP_TEMP_P1C_SigSts.Value, variation-point={short-label=vpIN_VeSR1B_y_EVAP_TEMP_P1C_SigSts_Value, sw-syscond=1}
            IN_VeSR1B_y_EVSE_OfdACSingPhasFD11_SigSts_Value: accessed-variable=VeSR1B_y_EVSE_OfdACSingPhasFD11_SigSts.Value, variation-point={short-label=vpIN_VeSR1B_y_EVSE_OfdACSingPhasFD11_SigSts_Value, sw-syscond=1}
            IN_VeSR1B_y_GlobDrvMdRq_BCM_SigSts_Value: accessed-variable=VeSR1B_y_GlobDrvMdRq_BCM_SigSts.Value, variation-point={short-label=vpIN_VeSR1B_y_GlobDrvMdRq_BCM_SigSts_Value, sw-syscond=1}
            IN_VeSR1B_y_IBS3_SOC_Accuracy_SigSts_Value: accessed-variable=VeSR1B_y_IBS3_SOC_Accuracy_SigSts.Value, variation-point={short-label=vpIN_VeSR1B_y_IBS3_SOC_Accuracy_SigSts_Value, sw-syscond=1}
            IN_VeSR1B_y_IMPACTCommand_FD14_SigSts_Value: accessed-variable=VeSR1B_y_IMPACTCommand_FD14_SigSts.Value, variation-point={short-label=vpIN_VeSR1B_y_IMPACTCommand_FD14_SigSts_Value, sw-syscond=1}
            IN_VeSR1B_y_KeyInIgnSts_SigSts_Value: accessed-variable=VeSR1B_y_KeyInIgnSts_SigSts.Value, variation-point={short-label=vpIN_VeSR1B_y_KeyInIgnSts_SigSts_Value, sw-syscond=1}
            IN_VeSR1B_y_LHF_Spin_FD3_SigSts_Value: accessed-variable=VeSR1B_y_LHF_Spin_FD3_SigSts.Value, variation-point={short-label=vpIN_VeSR1B_y_LHF_Spin_FD3_SigSts_Value, sw-syscond=1}
            IN_VeSR1B_y_LatAcceleration_FD14_SigSts_Value: accessed-variable=VeSR1B_y_LatAcceleration_FD14_SigSts.Value, variation-point={short-label=vpIN_VeSR1B_y_LatAcceleration_FD14_SigSts_Value, sw-syscond=1}
            IN_VeSR1B_y_LatAcceltnOffset_BSM_SigSts_Value: accessed-variable=VeSR1B_y_LatAcceltnOffset_BSM_SigSts.Value, variation-point={short-label=vpIN_VeSR1B_y_LatAcceltnOffset_BSM_SigSts_Value, sw-syscond=1}
            IN_VeSR1B_y_MCPA_6SO_Status_P_FD16_SigSts_Value: accessed-variable=VeSR1B_y_MCPA_6SO_Status_P_FD16_SigSts.Value, variation-point={short-label=vpIN_VeSR1B_y_MCPA_6SO_Status_P_FD16_SigSts_Value, sw-syscond=1}
            IN_VeSR1B_y_MCPA_6SO_Status_P_FD5_SigSts_Value: accessed-variable=VeSR1B_y_MCPA_6SO_Status_P_FD5_SigSts.Value, variation-point={short-label=vpIN_VeSR1B_y_MCPA_6SO_Status_P_FD5_SigSts_Value, sw-syscond=1}
            IN_VeSR1B_y_MCPA_Cal_ID_Idx_FD16_SigSts_Value: accessed-variable=VeSR1B_y_MCPA_Cal_ID_Idx_FD16_SigSts.Value, variation-point={short-label=vpIN_VeSR1B_y_MCPA_Cal_ID_Idx_FD16_SigSts_Value, sw-syscond=1}
            IN_VeSR1B_y_MCPA_Cal_ID_Idx_FD5_SigSts_Value: accessed-variable=VeSR1B_y_MCPA_Cal_ID_Idx_FD5_SigSts.Value, variation-point={short-label=vpIN_VeSR1B_y_MCPA_Cal_ID_Idx_FD5_SigSts_Value, sw-syscond=1}
            IN_VeSR1B_y_MCPB_6SO_Status_P_FD16_SigSts_Value: accessed-variable=VeSR1B_y_MCPB_6SO_Status_P_FD16_SigSts.Value, variation-point={short-label=vpIN_VeSR1B_y_MCPB_6SO_Status_P_FD16_SigSts_Value, sw-syscond=1}
            IN_VeSR1B_y_MCPB_6SO_Status_P_FD5_SigSts_Value: accessed-variable=VeSR1B_y_MCPB_6SO_Status_P_FD5_SigSts.Value, variation-point={short-label=vpIN_VeSR1B_y_MCPB_6SO_Status_P_FD5_SigSts_Value, sw-syscond=1}
            IN_VeSR1B_y_MCPB_Cal_ID_Idx_FD16_SigSts_Value: accessed-variable=VeSR1B_y_MCPB_Cal_ID_Idx_FD16_SigSts.Value, variation-point={short-label=vpIN_VeSR1B_y_MCPB_Cal_ID_Idx_FD16_SigSts_Value, sw-syscond=1}
            IN_VeSR1B_y_MCPB_Cal_ID_Idx_FD5_SigSts_Value: accessed-variable=VeSR1B_y_MCPB_Cal_ID_Idx_FD5_SigSts.Value, variation-point={short-label=vpIN_VeSR1B_y_MCPB_Cal_ID_Idx_FD5_SigSts_Value, sw-syscond=1}
            IN_VeSR1B_y_REF_VEH_SPEED_FD14_SigSts_Value: accessed-variable=VeSR1B_y_REF_VEH_SPEED_FD14_SigSts.Value, variation-point={short-label=vpIN_VeSR1B_y_REF_VEH_SPEED_FD14_SigSts_Value, sw-syscond=1}
            IN_VeSR1B_y_TSRSts_SigSts_Value: accessed-variable=VeSR1B_y_TSRSts_SigSts.Value, variation-point={short-label=vpIN_VeSR1B_y_TSRSts_SigSts_Value, sw-syscond=1}
        data-send-points:
          22 x access:
            OUT_VeCCMB_e_FaultSts_InvData_CADM_Value: accessed-variable=VeCCMB_e_FaultSts_InvData_CADM.Value, variation-point={short-label=vpOUT_VeCCMB_e_FaultSts_InvData_CADM_Value, sw-syscond=1}
            OUT_VeCCMB_e_FaultSts_InvData_CANC2_BCM_Value: accessed-variable=VeCCMB_e_FaultSts_InvData_CANC2_BCM.Value, variation-point={short-label=vpOUT_VeCCMB_e_FaultSts_InvData_CANC2_BCM_Value, sw-syscond=1}
            OUT_VeCCMB_e_FaultSts_InvData_ABS_BusB_Value: accessed-variable=VeCCMB_e_FaultSts_InvData_ABS_BusB.Value, variation-point={short-label=vpOUT_VeCCMB_e_FaultSts_InvData_ABS_BusB_Value, sw-syscond=1}
            OUT_VeCCMB_e_FaultSts_InvData_IDCM_CANC11_Value: accessed-variable=VeCCMB_e_FaultSts_InvData_IDCM_CANC11.Value, variation-point={short-label=vpOUT_VeCCMB_e_FaultSts_InvData_IDCM_CANC11_Value, sw-syscond=1}
            OUT_VeCCMB_e_FaultSts_InvData_ECM_A_CRC_MC_Value: accessed-variable=VeCCMB_e_FaultSts_InvData_ECM_A_CRC_MC.Value, variation-point={short-label=vpOUT_VeCCMB_e_FaultSts_InvData_ECM_A_CRC_MC_Value, sw-syscond=1}
            OUT_VeCCMB_e_FaultSts_InvData_DMCM_A_CRC_MC_Value: accessed-variable=VeCCMB_e_FaultSts_InvData_DMCM_A_CRC_MC.Value, variation-point={short-label=vpOUT_VeCCMB_e_FaultSts_InvData_DMCM_A_CRC_MC_Value, sw-syscond=1}
            OUT_VeCCMB_e_FaultSts_InvData_DMCM_B_CRC_MC_Value: accessed-variable=VeCCMB_e_FaultSts_InvData_DMCM_B_CRC_MC.Value, variation-point={short-label=vpOUT_VeCCMB_e_FaultSts_InvData_DMCM_B_CRC_MC_Value, sw-syscond=1}
            OUT_VeCCMB_e_FaultSts_InvData_BECM_CANC11_Value: accessed-variable=VeCCMB_e_FaultSts_InvData_BECM_CANC11.Value, variation-point={short-label=vpOUT_VeCCMB_e_FaultSts_InvData_BECM_CANC11_Value, sw-syscond=1}
            OUT_VeCCMB_e_FaultSts_InvData_DMCM_A_CANC11_Value: accessed-variable=VeCCMB_e_FaultSts_InvData_DMCM_A_CANC11.Value, variation-point={short-label=vpOUT_VeCCMB_e_FaultSts_InvData_DMCM_A_CANC11_Value, sw-syscond=1}
            OUT_VeCCMB_e_FaultSts_InvData_DMCM_B_CANC11_Value: accessed-variable=VeCCMB_e_FaultSts_InvData_DMCM_B_CANC11.Value, variation-point={short-label=vpOUT_VeCCMB_e_FaultSts_InvData_DMCM_B_CANC11_Value, sw-syscond=1}
            OUT_VeCCMB_e_FaultSts_InvData_ABSCM_A_Value: accessed-variable=VeCCMB_e_FaultSts_InvData_ABSCM_A.Value, variation-point={short-label=vpOUT_VeCCMB_e_FaultSts_InvData_ABSCM_A_Value, sw-syscond=1}
            OUT_VeCCMB_e_FaultSts_InvData_ORC_Value: accessed-variable=VeCCMB_e_FaultSts_InvData_ORC.Value, variation-point={short-label=vpOUT_VeCCMB_e_FaultSts_InvData_ORC_Value, sw-syscond=1}
            OUT_VeCCMB_e_FaultSts_LosCommBECM_A_Value: accessed-variable=VeCCMB_e_FaultSts_LosCommBECM_A.Value, variation-point={short-label=vpOUT_VeCCMB_e_FaultSts_LosCommBECM_A_Value, sw-syscond=1}
            OUT_VeCCMB_e_FaultSts_LostComm_DMCM_A_ePT2_Value: accessed-variable=VeCCMB_e_FaultSts_LostComm_DMCM_A_ePT2.Value, variation-point={short-label=vpOUT_VeCCMB_e_FaultSts_LostComm_DMCM_A_ePT2_Value, sw-syscond=1}
            OUT_VeCCMB_e_FaultSts_LostComm_DMCM_B_Value: accessed-variable=VeCCMB_e_FaultSts_LostComm_DMCM_B.Value, variation-point={short-label=vpOUT_VeCCMB_e_FaultSts_LostComm_DMCM_B_Value, sw-syscond=1}
            OUT_VeCCMB_e_FaultSts_InvData_ESM_CRC_MC_Value: accessed-variable=VeCCMB_e_FaultSts_InvData_ESM_CRC_MC.Value, variation-point={short-label=vpOUT_VeCCMB_e_FaultSts_InvData_ESM_CRC_MC_Value, sw-syscond=1}
            OUT_VeCCMB_e_FaultSts_InvData_CCN_CRC_MC_Value: accessed-variable=VeCCMB_e_FaultSts_InvData_CCN_CRC_MC.Value, variation-point={short-label=vpOUT_VeCCMB_e_FaultSts_InvData_CCN_CRC_MC_Value, sw-syscond=1}
            OUT_VeCCMB_e_FaultSts_InvData_ESM_BusB_Value: accessed-variable=VeCCMB_e_FaultSts_InvData_ESM_BusB.Value, variation-point={short-label=vpOUT_VeCCMB_e_FaultSts_InvData_ESM_BusB_Value, sw-syscond=1}
            OUT_VeCCMB_e_FaultSts_InvData_IDCM_Value: accessed-variable=VeCCMB_e_FaultSts_InvData_IDCM.Value, variation-point={short-label=vpOUT_VeCCMB_e_FaultSts_InvData_IDCM_Value, sw-syscond=1}
            OUT_VeCCMB_e_FaultSts_LostComm_BCCM_C_Value: accessed-variable=VeCCMB_e_FaultSts_LostComm_BCCM_C.Value, variation-point={short-label=vpOUT_VeCCMB_e_FaultSts_LostComm_BCCM_C_Value, sw-syscond=1}
            OUT_VeCCMB_e_FaultSts_LostCommISM_Value: accessed-variable=VeCCMB_e_FaultSts_LostCommISM.Value, variation-point={short-label=vpOUT_VeCCMB_e_FaultSts_LostCommISM_Value, sw-syscond=1}
            OUT_VeCCMB_e_FaultSts_InvData_AutoDrvSys_CM_A_Value: accessed-variable=VeCCMB_e_FaultSts_InvData_AutoDrvSys_CM_A.Value, variation-point={short-label=vpOUT_VeCCMB_e_FaultSts_InvData_AutoDrvSys_CM_A_Value, sw-syscond=1}
      4 x variation point proxy, all with category=CONDITION:
        Variant_CCMB_BLUEN: condition-access=0
        Variant_CCMB_COREBEV: condition-access=1
        Variant_CCMB_COREBEV_MY24: condition-access=0
        Variant_CCMB_PEGASUS: condition-access=0
